# aif2 register map
Vendor: Texas Instruments
Peripheral module from a debugger description file (folder Keystone2).
Registers are 32-bit, read-write, no defined reset value unless marked. A register's access mark holds for its fields unless they carry their own. Offsets are as the file gives them; lines under a group give offsets from that group; [hi:lo] are bit positions; {n}, {i} and the like mark numbered series; 'fields as' and 'values as' point back to an identical list; <NAME> marks a mode.

## AIF2 (part 1 of 3)
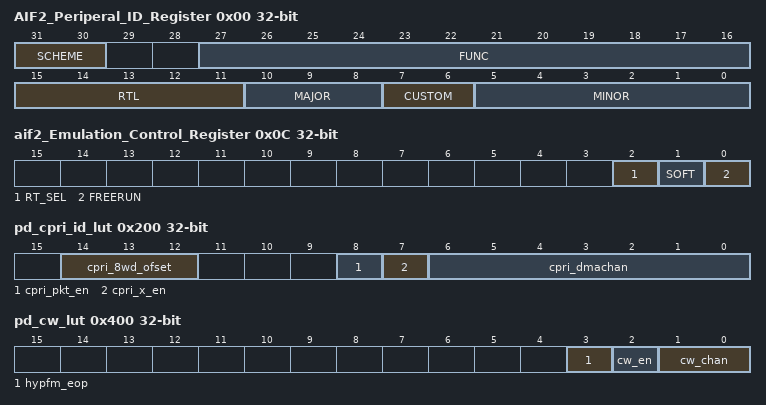
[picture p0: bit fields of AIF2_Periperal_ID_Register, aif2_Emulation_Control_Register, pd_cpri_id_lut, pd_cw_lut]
0x00 AIF2_Periperal_ID_Register ro
  [31:30] SCHEME — Current scheme
  [27:16] FUNC — Function code assigned to AIF2
  [15:11] RTL — RTL Version R code
  [10:8] MAJOR — Major revision X code
  [7:6] CUSTOM — Custom version code
  [5:0] MINOR — Minor revision Y code
0x04 AIF2_Scratch_Register — VC Scratch Register
  [31:0] Scratch — This is the VC Scratch Field.
0x08 AIF2_sw_reset wo — at sw sync
  [0] sw_rst — AIF2 software reset pulse
0x0C aif2_Emulation_Control_Register
  [2] RT_SEL — RT_SEL bit
  [1] SOFT — SOFT bit. This bit is ignored by the AIF2. AIF2 always performs a graceful SOFT stop
  [0] FREERUN — FREERUN bit
0x10 VC_Status_Register ro
  [0] EMU_HALT — Emulation halt status
0x200 pd_cpri_id_lut — (1 of 128, stride 4)
  [14:12] cpri_8wd_ofset — Fine AxC offset. Used in the front end of PD to align word data into QWords. bit \[1:0\] are offset into a QWord. bit\[2\] give RSA double QWork alignment. Bit\[2\] and corresponding axc_offset\[0\] should always be programmed to be identical
  [8] cpri_pkt_en — DBMF CPRI Stream LUT: dicates the cpri payload is to be used as AxC (normal) or Packet traffic. (note: the concept of packet traffic in CPRI payload is a feature extention of CPRI)
  [7] cpri_x_en — DBMF CPRI Stream LUT: enable-disable of channel, for each value of DBM X count.
  [6:0] cpri_dmachan — DBMF CPRI Stream LUT: AxC:used to map DBM X count to DMA channel. PKT:2 lsb indicates 0-3 PKT packing circuit (assumed 4B/5B encoding)
0x400 pd_cw_lut — (1 of 256, stride 4)
  [3] hypfm_eop — All possible CPRI CW per hyperframe. (Used for pkt_delim_ch HyperFrame delineation)Identifies last CW per HyperFrame for this channel
  [2] cw_en — All possible CPRI CW per hyperframe. Dicatates whether the control word should be captured at all
  [1:0] cw_chan — All possible CPRI CW per hyperframe are are mapped to one of four CPRI CW staging areas. This allow CPRI CW to be split into 4 differen streams.
0x4000 EE_VB_End_of_Interrupt_Register — This register supports the End of Interrupt (EOI) interface between the AIF2 and the external Interrupt Distributor Component used in the Highlander 0.1 Interrupt Architecture. It is a common register that is used for servicing both of the AIF2
  [7:0] eoi_vector — End of interrupt vector value that distinguishes which interrupt is being acknowledged. This value is outputted on the external eoi_vector interface of the AIF2.
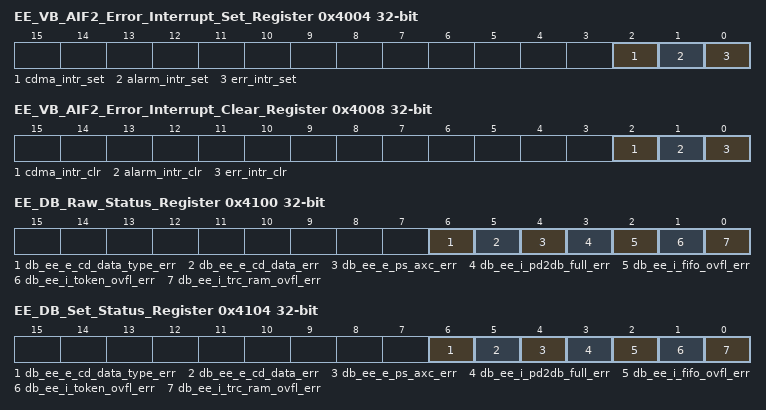
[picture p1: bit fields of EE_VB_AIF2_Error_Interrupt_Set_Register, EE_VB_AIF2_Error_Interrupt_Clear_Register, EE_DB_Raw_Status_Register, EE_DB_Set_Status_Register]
0x4004 EE_VB_AIF2_Error_Interrupt_Set_Register wo — This register allows software to create an AIF2 Error Interrupt or AIF2 Alarm Interrupt by writing bits in this register. This register is provided for debug and diagnostics.
  [2] cdma_intr_set — AIF2 CDMA Interrupt Set.
  [1] alarm_intr_set — AIF2 Alarm Interrupt Set.
  [0] err_intr_set — AIF2 Error Interrupt Set.
0x4008 EE_VB_AIF2_Error_Interrupt_Clear_Register wo — This register allows software to clear an AIF2 Error Interrupt or AIF2 Alarm Interrupt by writing bits in this register. This register is provided for debug and diagnostics.
  [2] cdma_intr_clr — AIF2 CDMA Interrupt Clear.
  [1] alarm_intr_clr — AIF2 Alarm Interrupt Clear.
  [0] err_intr_clr — AIF2 Error Interrupt Clear.
0x4100 EE_DB_Raw_Status_Register ro
  [6] db_ee_e_cd_data_type_err — DB Engress CDMA Data Error.
  [5] db_ee_e_cd_data_err — DB Ingress CDMA Data Error.
  [4] db_ee_e_ps_axc_err — DB Engress AXC Token Overflow Error.
  [3] db_ee_i_pd2db_full_err — DB Engress PM Token Overflow Error.
  [2] db_ee_i_fifo_ovfl_err — DB Ingress FIFO Overflow Error.
  [1] db_ee_i_token_ovfl_err — DB Ingress Token Overflow Error.
  [0] db_ee_i_trc_ram_ovfl_err — DB Ingress TRC Token Overflow Error.
0x4104 EE_DB_Set_Status_Register wo
  [6] db_ee_e_cd_data_type_err — DB Engress CDMA Data Error Set.
  [5] db_ee_e_cd_data_err — DB Ingress CDMA Data Error Set.
  [4] db_ee_e_ps_axc_err — DB Engress AXC Token Overflow Error Set.
  [3] db_ee_i_pd2db_full_err — DB Engress PM Token Overflow Error Set.
  [2] db_ee_i_fifo_ovfl_err — DB Ingress FIFO Overflow Error Set.
  [1] db_ee_i_token_ovfl_err — DB Ingress Token Overflow Error Set.
  [0] db_ee_i_trc_ram_ovfl_err — DB Ingress TRC Token Overflow Error Set.
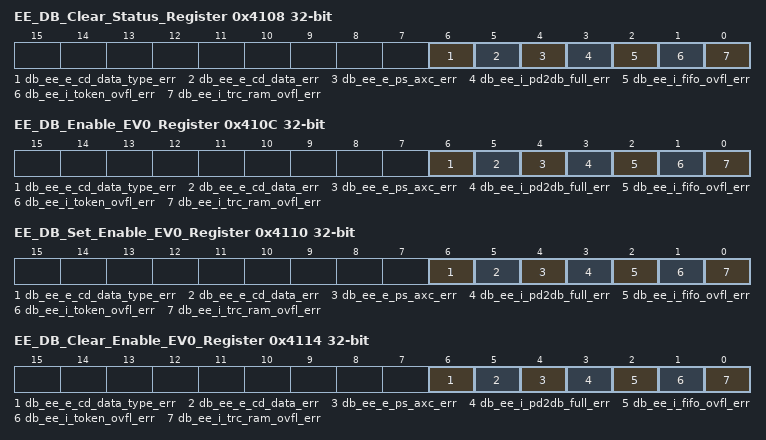
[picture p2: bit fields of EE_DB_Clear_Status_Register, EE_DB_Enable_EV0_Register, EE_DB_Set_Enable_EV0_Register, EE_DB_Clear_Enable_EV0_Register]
0x4108 EE_DB_Clear_Status_Register wo
  [6] db_ee_e_cd_data_type_err — DB Engress CDMA Data Error Clear.
  [5] db_ee_e_cd_data_err — DB Ingress CDMA Data Error Clear.
  [4] db_ee_e_ps_axc_err — DB Engress AXC Token Overflow Error Clear.
  [3] db_ee_i_pd2db_full_err — DB Engress PM Token Overflow Error Clear.
  [2] db_ee_i_fifo_ovfl_err — DB Ingress FIFO Overflow Error Clear.
  [1] db_ee_i_token_ovfl_err — DB Ingress Token Overflow Error Clear.
  [0] db_ee_i_trc_ram_ovfl_err — DB Ingress TRC Token Overflow Error Clear.
0x410C EE_DB_Enable_EV0_Register ro
  [6] db_ee_e_cd_data_type_err — DB Engress CDMA Data Error Enable.
  [5] db_ee_e_cd_data_err — DB Ingress CDMA Data Error Enable.
  [4] db_ee_e_ps_axc_err — DB Engress AXC Token Overflow Error Enable.
  [3] db_ee_i_pd2db_full_err — DB Engress PM Token Overflow Error Enable.
  [2] db_ee_i_fifo_ovfl_err — DB Ingress FIFO Overflow Error Enable.
  [1] db_ee_i_token_ovfl_err — DB Ingress Token Overflow Error Enable.
  [0] db_ee_i_trc_ram_ovfl_err — DB Ingress TRC Token Overflow Error Enable.
0x4110 EE_DB_Set_Enable_EV0_Register wo
  [6] db_ee_e_cd_data_type_err — DB Engress CDMA Data Error Enable Set.
  [5] db_ee_e_cd_data_err — DB Ingress CDMA Data Error Enable Set.
  [4] db_ee_e_ps_axc_err — DB Engress AXC Token Overflow Error Enable Set.
  [3] db_ee_i_pd2db_full_err — DB Engress PM Token Overflow Error Enable Set.
  [2] db_ee_i_fifo_ovfl_err — DB Ingress FIFO Overflow Error Enable Set.
  [1] db_ee_i_token_ovfl_err — DB Ingress Token Overflow Error Enable Set.
  [0] db_ee_i_trc_ram_ovfl_err — DB Ingress TRC Token Overflow Error Enable Set.
0x4114 EE_DB_Clear_Enable_EV0_Register wo
  [6] db_ee_e_cd_data_type_err — DB Engress CDMA Data Error Enable Clear.
  [5] db_ee_e_cd_data_err — DB Ingress CDMA Data Error Enable Clear.
  [4] db_ee_e_ps_axc_err — DB Engress AXC Token Overflow Error Enable Clear.
  [3] db_ee_i_pd2db_full_err — DB Engress PM Token Overflow Error Enable Clear.
  [2] db_ee_i_fifo_ovfl_err — DB Ingress FIFO Overflow Error Enable Clear.
  [1] db_ee_i_token_ovfl_err — DB Ingress Token Overflow Error Enable Clear.
  [0] db_ee_i_trc_ram_ovfl_err — DB Ingress TRC Token Overflow Error Enable Clear.
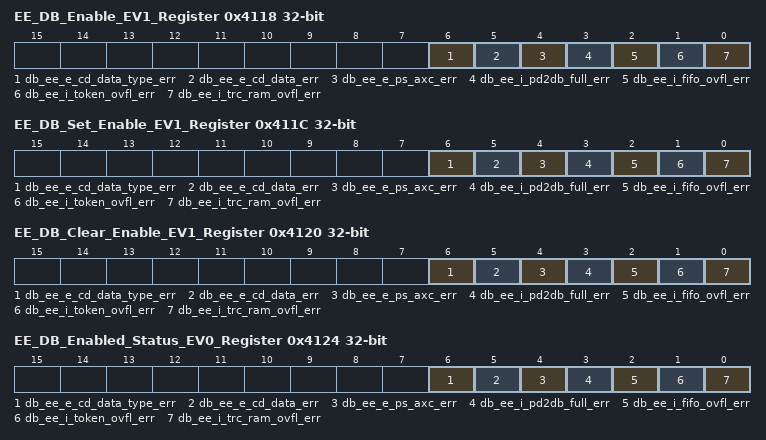
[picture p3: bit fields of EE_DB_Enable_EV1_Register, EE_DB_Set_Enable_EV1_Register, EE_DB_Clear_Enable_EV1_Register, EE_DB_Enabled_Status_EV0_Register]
0x4118 EE_DB_Enable_EV1_Register ro
  fields as EE_DB_Enable_EV0_Register
0x411C EE_DB_Set_Enable_EV1_Register wo
  fields as EE_DB_Set_Enable_EV0_Register
0x4120 EE_DB_Clear_Enable_EV1_Register wo
  fields as EE_DB_Clear_Enable_EV0_Register
0x4124 EE_DB_Enabled_Status_EV0_Register ro
  [6] db_ee_e_cd_data_type_err — DB Engress CDMA Data Error Enabled.
  [5] db_ee_e_cd_data_err — DB Ingress CDMA Data Error Enabled.
  [4] db_ee_e_ps_axc_err — DB Engress AXC Token Overflow Error Enabled.
  [3] db_ee_i_pd2db_full_err — DB Engress PM Token Overflow Error Enabled.
  [2] db_ee_i_fifo_ovfl_err — DB Ingress FIFO Overflow Error Enabled.
  [1] db_ee_i_token_ovfl_err — DB Ingress Token Overflow Error Enabled.
  [0] db_ee_i_trc_ram_ovfl_err — DB Ingress TRC Token Overflow Error Enabled.
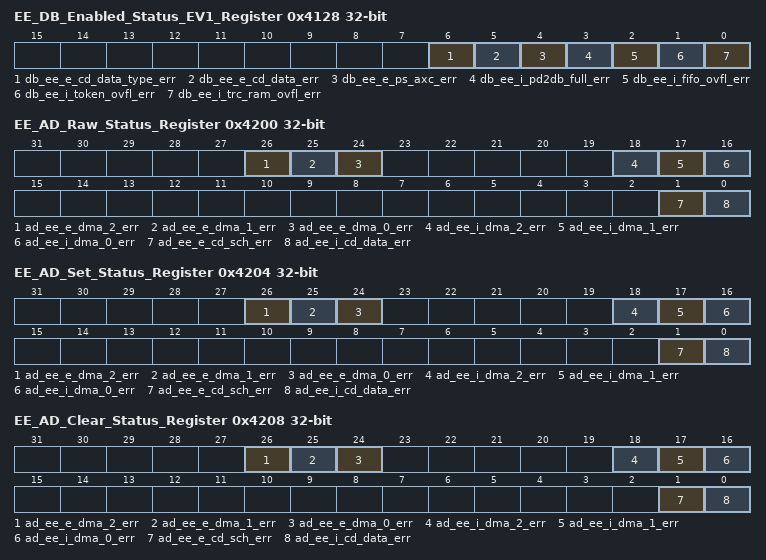
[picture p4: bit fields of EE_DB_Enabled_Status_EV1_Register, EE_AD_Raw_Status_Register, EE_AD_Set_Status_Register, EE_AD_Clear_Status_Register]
0x4128 EE_DB_Enabled_Status_EV1_Register ro
  fields as EE_DB_Enabled_Status_EV0_Register
0x4200 EE_AD_Raw_Status_Register ro
  [26] ad_ee_e_dma_2_err — AD Egress DMA Bit 2 Error.
  [25] ad_ee_e_dma_1_err — AD Egress DMA Bit 1 Error.
  [24] ad_ee_e_dma_0_err — AD Egress DMA Bit 0 Error.
  [18] ad_ee_i_dma_2_err — AD Ingress DMA Bit 2 Error.
  [17] ad_ee_i_dma_1_err — AD Ingress DMA Bit 1 Error.
  [16] ad_ee_i_dma_0_err — AD Ingress DMA Bit 0 Error.
  [1] ad_ee_e_cd_sch_err — AD Engress CDMA Scheduler Error.
  [0] ad_ee_i_cd_data_err — AD Egress CDMA Data Error.
0x4204 EE_AD_Set_Status_Register wo
  [26] ad_ee_e_dma_2_err — AD Egress DMA Bit 2 Error Set.
  [25] ad_ee_e_dma_1_err — AD Egress DMA Bit 1 Error Set.
  [24] ad_ee_e_dma_0_err — AD Egress DMA Bit 0 Error Set.
  [18] ad_ee_i_dma_2_err — AD Ingress DMA Bit 2 Error Set.
  [17] ad_ee_i_dma_1_err — AD Ingress DMA Bit 1 Error Set.
  [16] ad_ee_i_dma_0_err — AD Ingress DMA Bit 0 Error Set.
  [1] ad_ee_e_cd_sch_err — AD Engress CDMA Scheduler Error Set.
  [0] ad_ee_i_cd_data_err — AD Egress CDMA Data Error Set.
0x4208 EE_AD_Clear_Status_Register wo
  [26] ad_ee_e_dma_2_err — AD Egress DMA Bit 2 Error Clear.
  [25] ad_ee_e_dma_1_err — AD Egress DMA Bit 1 Error Clear.
  [24] ad_ee_e_dma_0_err — AD Egress DMA Bit 0 Error Clear.
  [18] ad_ee_i_dma_2_err — AD Ingress DMA Bit 2 Error Clear.
  [17] ad_ee_i_dma_1_err — AD Ingress DMA Bit 1 Error Clear.
  [16] ad_ee_i_dma_0_err — AD Ingress DMA Bit 0 Error Clear.
  [1] ad_ee_e_cd_sch_err — AD Engress CDMA Scheduler Error Clear.
  [0] ad_ee_i_cd_data_err — AD Egress CDMA Data Error Clear.
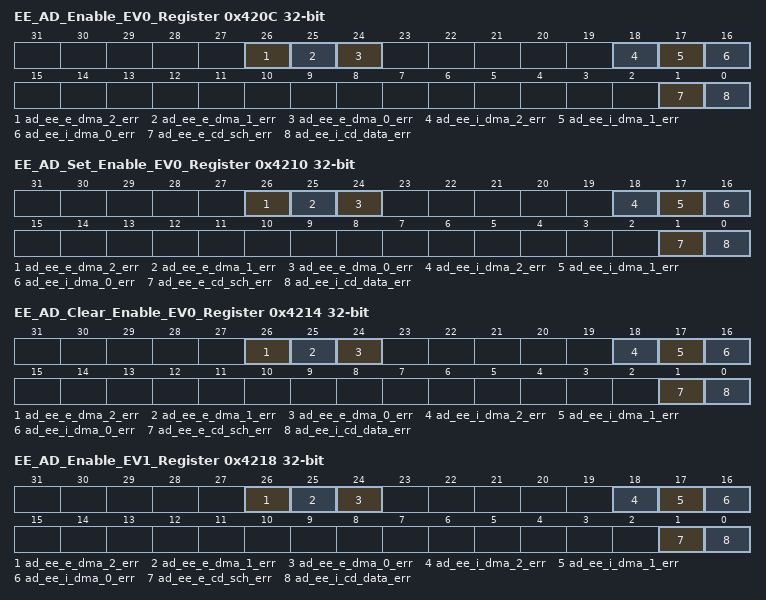
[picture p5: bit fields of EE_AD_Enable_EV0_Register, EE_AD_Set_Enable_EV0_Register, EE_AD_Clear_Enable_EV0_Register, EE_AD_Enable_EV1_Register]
0x420C EE_AD_Enable_EV0_Register ro
  [26] ad_ee_e_dma_2_err — AD Egress DMA Bit 2 Error Enable.
  [25] ad_ee_e_dma_1_err — AD Egress DMA Bit 1 Error Enable.
  [24] ad_ee_e_dma_0_err — AD Egress DMA Bit 0 Error Enable.
  [18] ad_ee_i_dma_2_err — AD Ingress DMA Bit 2 Error Enable.
  [17] ad_ee_i_dma_1_err — AD Ingress DMA Bit 1 Error Enable.
  [16] ad_ee_i_dma_0_err — AD Ingress DMA Bit 0 Error Enable.
  [1] ad_ee_e_cd_sch_err — AD Engress CDMA Scheduler Error Enable.
  [0] ad_ee_i_cd_data_err — AD Egress CDMA Data Error Enable.
0x4210 EE_AD_Set_Enable_EV0_Register wo
  [26] ad_ee_e_dma_2_err — AD Egress DMA Bit 2 Error Enable Set.
  [25] ad_ee_e_dma_1_err — AD Egress DMA Bit 1 Error Enable Set.
  [24] ad_ee_e_dma_0_err — AD Egress DMA Bit 0 Error Enable Set.
  [18] ad_ee_i_dma_2_err — AD Ingress DMA Bit 2 Error Enable Set.
  [17] ad_ee_i_dma_1_err — AD Ingress DMA Bit 1 Error Enable Set.
  [16] ad_ee_i_dma_0_err — AD Ingress DMA Bit 0 Error Enable Set.
  [1] ad_ee_e_cd_sch_err — AD Engress CDMA Scheduler Error Enable Set.
  [0] ad_ee_i_cd_data_err — AD Egress CDMA Data Error Enable Set.
0x4214 EE_AD_Clear_Enable_EV0_Register wo
  [26] ad_ee_e_dma_2_err — AD Egress DMA Bit 2 Error Enable Clear.
  [25] ad_ee_e_dma_1_err — AD Egress DMA Bit 1 Error Enable Clear.
  [24] ad_ee_e_dma_0_err — AD Egress DMA Bit 0 Error Enable Clear.
  [18] ad_ee_i_dma_2_err — AD Ingress DMA Bit 2 Error Enable Clear.
  [17] ad_ee_i_dma_1_err — AD Ingress DMA Bit 1 Error Enable Clear.
  [16] ad_ee_i_dma_0_err — AD Ingress DMA Bit 0 Error Enable Clear.
  [1] ad_ee_e_cd_sch_err — AD Engress CDMA Scheduler Error Enable Clear.
  [0] ad_ee_i_cd_data_err — AD Egress CDMA Data Error Enable Clear.
0x4218 EE_AD_Enable_EV1_Register ro
  fields as EE_AD_Enable_EV0_Register
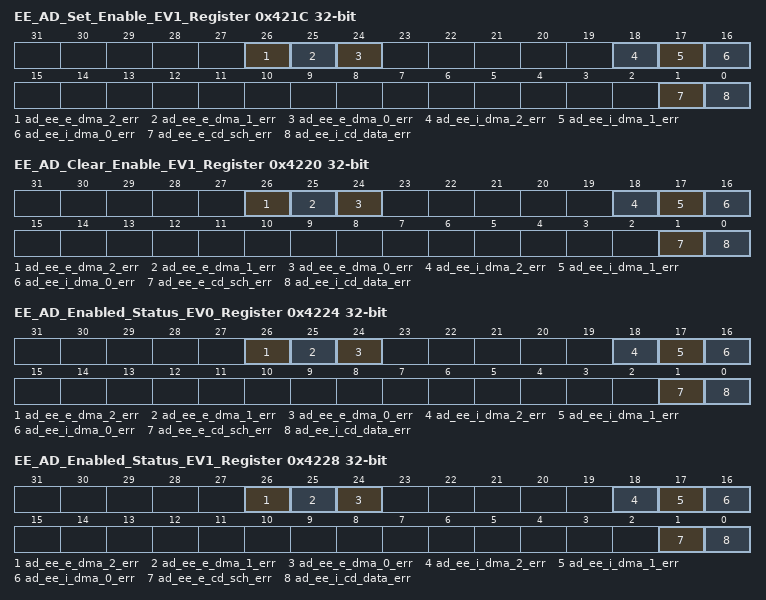
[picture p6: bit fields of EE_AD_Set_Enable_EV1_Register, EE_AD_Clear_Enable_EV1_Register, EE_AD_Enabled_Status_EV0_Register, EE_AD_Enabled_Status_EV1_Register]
0x421C EE_AD_Set_Enable_EV1_Register wo
  fields as EE_AD_Set_Enable_EV0_Register
0x4220 EE_AD_Clear_Enable_EV1_Register wo
  fields as EE_AD_Clear_Enable_EV0_Register
0x4224 EE_AD_Enabled_Status_EV0_Register ro
  [26] ad_ee_e_dma_2_err — AD Egress DMA Bit 2 Error Enabled.
  [25] ad_ee_e_dma_1_err — AD Egress DMA Bit 1 Error Enabled.
  [24] ad_ee_e_dma_0_err — AD Egress DMA Bit 0 Error Enabled.
  [18] ad_ee_i_dma_2_err — AD Ingress DMA Bit 2 Error Enabled.
  [17] ad_ee_i_dma_1_err — AD Ingress DMA Bit 1 Error Enabled.
  [16] ad_ee_i_dma_0_err — AD Ingress DMA Bit 0 Error Enabled.
  [1] ad_ee_e_cd_sch_err — AD Engress CDMA Scheduler Error Enabled.
  [0] ad_ee_i_cd_data_err — AD Egress CDMA Data Error Enabled.
0x4228 EE_AD_Enabled_Status_EV1_Register ro
  fields as EE_AD_Enabled_Status_EV0_Register
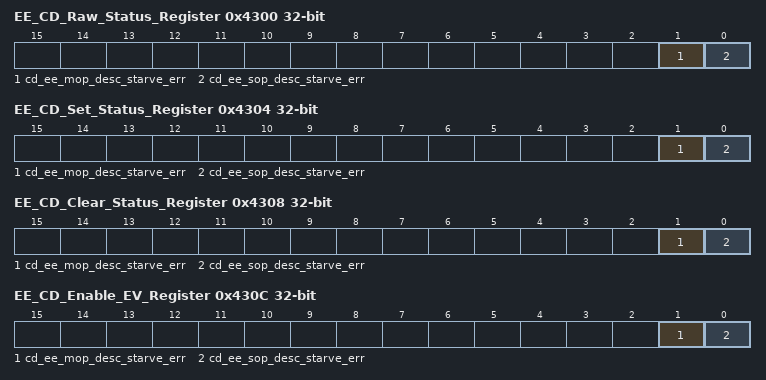
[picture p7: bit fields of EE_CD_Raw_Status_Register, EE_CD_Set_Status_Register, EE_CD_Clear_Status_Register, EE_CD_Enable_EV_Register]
0x4300 EE_CD_Raw_Status_Register ro
  [1] cd_ee_mop_desc_starve_err — CD MOP Desc. Starve Error.
  [0] cd_ee_sop_desc_starve_err — CD SOP Desc. Starve Error.
0x4304 EE_CD_Set_Status_Register wo
  [1] cd_ee_mop_desc_starve_err — CD MOP Desc. Starve Error Set.
  [0] cd_ee_sop_desc_starve_err — CD SOP Desc. Starve Error Set.
0x4308 EE_CD_Clear_Status_Register wo
  [1] cd_ee_mop_desc_starve_err — CD MOP Desc. Starve Error Clear.
  [0] cd_ee_sop_desc_starve_err — CD SOP Desc. Starve Error Clear.
0x430C EE_CD_Enable_EV_Register ro — EE CD Enable EV0 Register
  [1] cd_ee_mop_desc_starve_err — CD MOP Desc. Starve Error Enable.
  [0] cd_ee_sop_desc_starve_err — CD SOP Desc. Starve Error Enable.
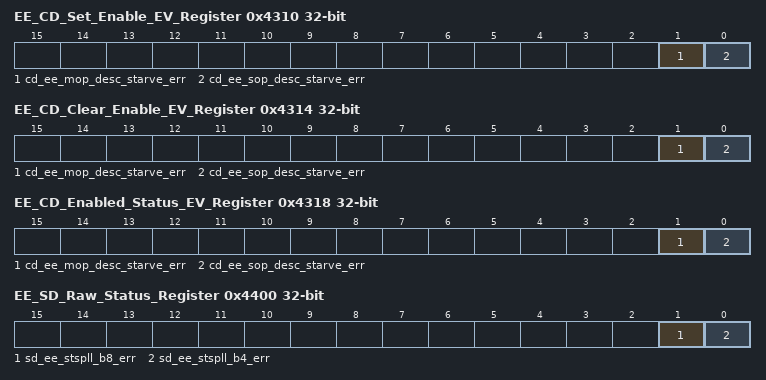
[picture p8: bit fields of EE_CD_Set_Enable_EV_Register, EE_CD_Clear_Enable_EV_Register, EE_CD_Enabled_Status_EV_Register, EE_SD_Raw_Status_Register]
0x4310 EE_CD_Set_Enable_EV_Register wo — EE CD Set Enable EV0 Register
  [1] cd_ee_mop_desc_starve_err — CD MOP Desc. Starve Error Enable Set.
  [0] cd_ee_sop_desc_starve_err — CD SOP Desc. Starve Error Enable Set.
0x4314 EE_CD_Clear_Enable_EV_Register wo — EE CD Clear Enable EV0 Register
  [1] cd_ee_mop_desc_starve_err — CD MOP Desc. Starve Error Enable Clear.
  [0] cd_ee_sop_desc_starve_err — CD SOP Desc. Starve Error Enable Clear.
0x4318 EE_CD_Enabled_Status_EV_Register ro — EE CD Enabled Status EV0 Register
  [1] cd_ee_mop_desc_starve_err — CD MOP Desc. Starve Error Enabled.
  [0] cd_ee_sop_desc_starve_err — CD SOP Desc. Starve Error Enabled.
0x4400 EE_SD_Raw_Status_Register ro
  [1] sd_ee_stspll_b8_err — SD B8 PLL Error.
  [0] sd_ee_stspll_b4_err — SD B4 PLL Error.
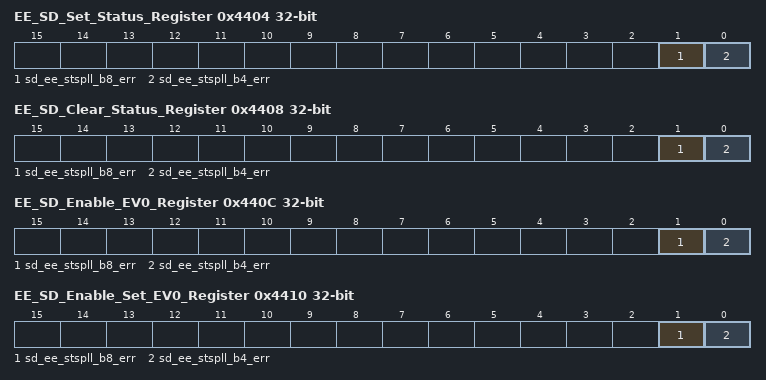
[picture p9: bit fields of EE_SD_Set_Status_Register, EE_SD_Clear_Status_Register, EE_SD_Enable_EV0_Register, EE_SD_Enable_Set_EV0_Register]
0x4404 EE_SD_Set_Status_Register wo
  [1] sd_ee_stspll_b8_err — SD B8 PLL Error Set.
  [0] sd_ee_stspll_b4_err — SD B4 PLL Error Set.
0x4408 EE_SD_Clear_Status_Register wo
  [1] sd_ee_stspll_b8_err — SD B8 PLL Error Clear
  [0] sd_ee_stspll_b4_err — SD B4 PLL Error Clear
0x440C EE_SD_Enable_EV0_Register ro
  [1] sd_ee_stspll_b8_err — SD B8 PLL Error Enable.
  [0] sd_ee_stspll_b4_err — SD B4 PLL Error Enable.
0x4410 EE_SD_Enable_Set_EV0_Register wo
  [1] sd_ee_stspll_b8_err — SD B8 PLL Error Set Enable.
  [0] sd_ee_stspll_b4_err — SD B4 PLL Error Set Enable.
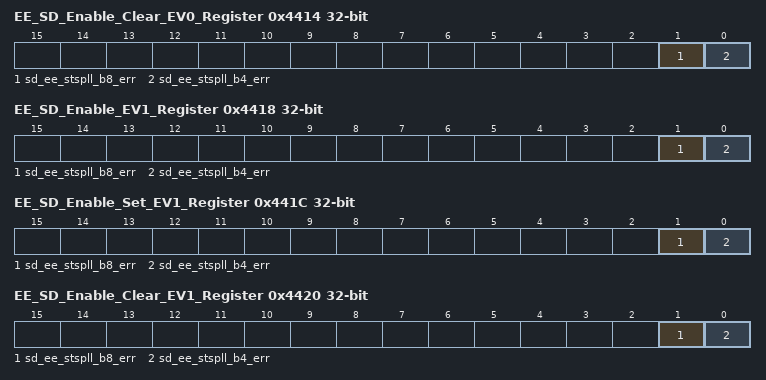
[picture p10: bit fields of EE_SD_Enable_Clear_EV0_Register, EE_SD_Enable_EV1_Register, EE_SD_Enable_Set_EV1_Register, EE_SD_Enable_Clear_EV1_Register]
0x4414 EE_SD_Enable_Clear_EV0_Register wo
  [1] sd_ee_stspll_b8_err — SD B8 PLL Error Clear Enable.
  [0] sd_ee_stspll_b4_err — SD B4 PLL Error Clear Enable.
0x4418 EE_SD_Enable_EV1_Register ro
  fields as EE_SD_Enable_EV0_Register
0x441C EE_SD_Enable_Set_EV1_Register wo
  fields as EE_SD_Enable_Set_EV0_Register
0x4420 EE_SD_Enable_Clear_EV1_Register wo
  fields as EE_SD_Enable_Clear_EV0_Register
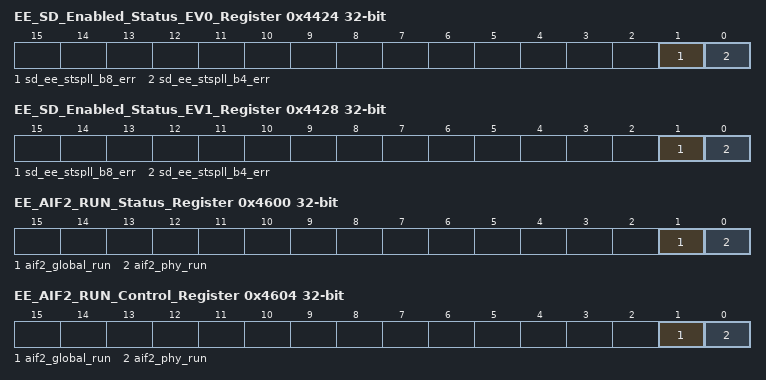
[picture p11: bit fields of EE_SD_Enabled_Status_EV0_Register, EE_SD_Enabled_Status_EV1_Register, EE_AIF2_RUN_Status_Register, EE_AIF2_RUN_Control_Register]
0x4424 EE_SD_Enabled_Status_EV0_Register ro
  [1] sd_ee_stspll_b8_err — SD B8 PLL Error Enabled.
  [0] sd_ee_stspll_b4_err — SD B4 PLL Error Enabled.
0x4428 EE_SD_Enabled_Status_EV1_Register ro
  fields as EE_SD_Enabled_Status_EV0_Register
0x4500 EE_VC_Raw_Status_Register ro
  [0] vc_ee_vbus_err — SD B4 PLL Error.
0x4504 EE_VC_Set_Status_Register wo
  [0] vc_ee_vbus_err — EE VC VBUS Error Set.
0x4508 EE_VC_Clear_Status_Register wo
  [0] vc_ee_vbus_err — EE VC VBUS Error Clear
0x450C EE_VC_Enable_EV0_Register ro
  [0] vc_ee_vbus_err — EE VC VBUS Error Enable.
0x4510 EE_VC_Enable_Set_EV0_Register wo
  [0] vc_ee_vbus_err — EE VC VBUS Error Set Enable.
0x4514 EE_VC_Enable_Clear_EV0_Register wo
  [0] vc_ee_vbus_err — EE VC VBUS Error Clear Enable.
0x4518 EE_VC_Enable_EV1_Register ro
  [0] vc_ee_vbus_err — EE VC VBUS Error Enable.
0x451C EE_VC_Enable_Set_EV1_Register wo
  [0] vc_ee_vbus_err — EE VC VBUS Error Set Enable.
0x4520 EE_VC_Enable_Clear_EV1_Register wo
  [0] vc_ee_vbus_err — EE VC VBUS Error Clear Enable.
0x4524 EE_VC_Enabled_Status_EV0_Register ro
  [0] vc_ee_vbus_err — EE VC VBUS Error Enabled.
0x4528 EE_VC_Enabled_Status_EV1_Register ro
  [0] vc_ee_vbus_err — EE VC VBUS Error Enabled
0x4600 EE_AIF2_RUN_Status_Register ro — This register is used to indicate the state of AIF2
  [1] aif2_global_run — This bit indicates the overall state of the AIF2.
  [0] aif2_phy_run — This bit indicates the state of the AIF2 Phy section.
0x4604 EE_AIF2_RUN_Control_Register wo — This register is used to indicate the state of AIF2
  fields as EE_AIF2_RUN_Status_Register
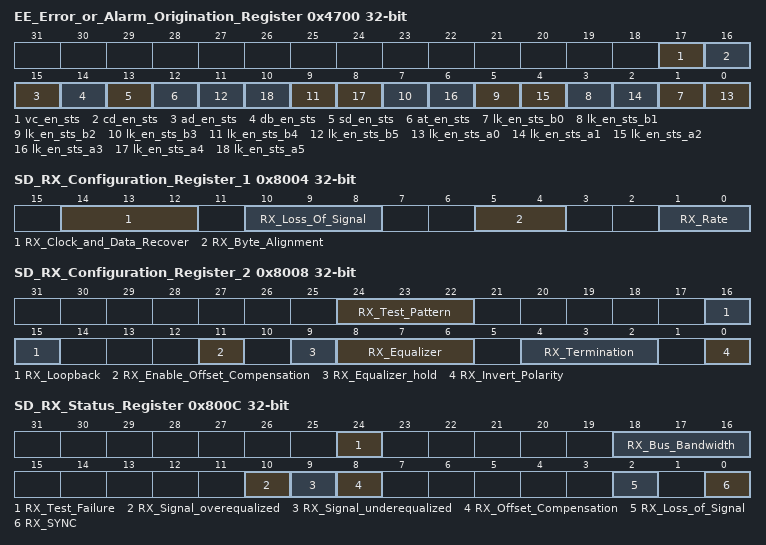
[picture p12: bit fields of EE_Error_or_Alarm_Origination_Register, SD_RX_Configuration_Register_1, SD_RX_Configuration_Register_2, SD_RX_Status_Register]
0x4700 EE_Error_or_Alarm_Origination_Register ro — EE Register used to determine which EN_STSregister contains the error/alarm that caused an event
  [17] vc_en_sts — VC_EN_STS register indication.
  [16] cd_en_sts — CD_EN_STS register indication.
  [15] ad_en_sts — AD_EN_STS register indication.
  [14] db_en_sts — DB_EN_STS register indication.
  [13] sd_en_sts — SD_EN_STS register indication.
  [12] at_en_sts — AT_EN_STS register indication.
  [2n+1] lk_en_sts_b{n} (n=0..5) — EE_LK_EN_STS_B{n} register indication.
  [2n] lk_en_sts_a{n} (n=0..5) — EE_LK_EN_STS_A{n} register indication.
0x8000 SD_RX_Enable_Configuration_Register — (1 of 6, stride 2048)
  [0] Enable_RX — The receiver Ser-des macro should be enabled once all the Ser-des configurations are complete, and the PLL has acquired lock.
0x8004 SD_RX_Configuration_Register_1 — (1 of 6, stride 2048)
  [14:12] RX_Clock_and_Data_Recover — Clock/data recovery. Configures the clock/data recovery algorithm.
  [10:8] RX_Loss_Of_Signal — The LOSi bits should be set to 2b10 to allow Loss of signal detection by the Ser-des macro.
  [5:4] RX_Byte_Alignment — The receiver frame synchronizer must control the byte alignment feature of each receiver so that a jog can be initiated based on detection of non-alignment. The ALIGNi bits must be set to 2b00 for normal operation.
  [1:0] RX_Rate — The AIF2 antenna interface link configuration registers must reflect the sample rate of each receiver as 2x, 4x, 8x so that the receiver logic is aware of the rate setting. These rates are listed in the following table.
0x8008 SD_RX_Configuration_Register_2 — (1 of 6, stride 2048)
  [24:22] RX_Test_Pattern — Enables and selects test patterns. Enables and selects verification of one of three PRBS patterns, a user defined pattern, or a clock test pattern.
  [16:15] RX_Loopback — The receiver frame synchronizer must have knowledge that each Ser-des port had been placed in Tx to Rx loopback so that the receiver can suppress events due to the realignment of the received frames. These bits should be set to 2b00 for normal operation.
  [11] RX_Enable_Offset_Compensation — Enable Offset Compensation. Enables samplers offset compensation.
  [9] RX_Equalizer_hold — Hold Equalizer. Holds equalizer in the current state.
  [8:6] RX_Equalizer — Equalizer. Enables and configures the equalizer to compensate for loss in the transmission media.
  [4:2] RX_Termination — Termination. Selects the input termination options suitable for AC or DC coupled scenarios.
  [0] RX_Invert_Polarity — Invert Polarity. Inverts the polarity of RXPi and RXNi.
0x800C SD_RX_Status_Register ro — (1 of 6, stride 2048)
  [24] RX_Test_Failure — Test Failure. Driven high when an error is encountered during a test sequence executed on an individual channel. Synchronous to RXBCLK.
  [18:16] RX_Bus_Bandwidth — The receiver bus bandwidth is fixed in hardware to 20 bits and is not configurable through an MMR. However the value that reflects a 20 bit bus width will be read of the configuration register is read.
  [10] RX_Signal_overequalized — Driven high during equalizer analysis if over equalized.
  [9] RX_Signal_underequalized — Driven high during equalizer analysis if under equalized.
  [8] RX_Offset_Compensation — Offset compensation in progress. Driven high asynchronously during offset compensation.
  [2] RX_Loss_of_Signal — The receiver frame synchronizer must have knowledge that each Ser-des port had detected a loss of signal condition so that the receiver can suppress events due to a loss of frame synchronization.
  [0] RX_SYNC — If the alignment feature of the Ser-des is used by hardware, the receiver frame synchronizer must have knowledge that each Ser-des port had completed a requested byte alignment so that the byte alignment control logic can operate.
0x8010 SD_TX_Enable_Configuration_Register — (1 of 6, stride 2048)
  [0] Enable_TX — The receiver Ser-des macro should be enabled once all the Ser-des configurations are complete, and the PLL has acquired lock.
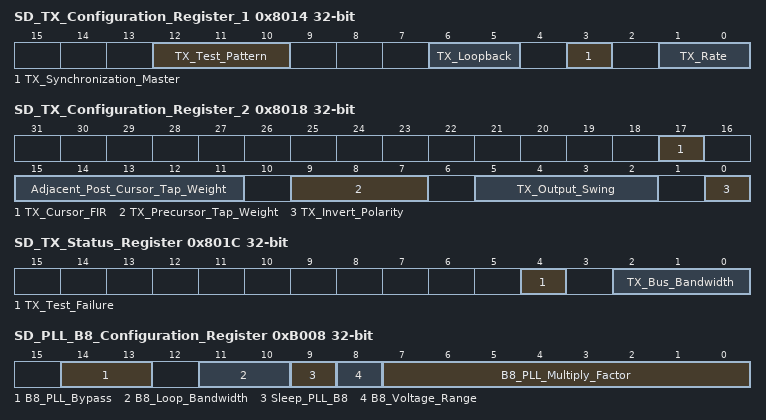
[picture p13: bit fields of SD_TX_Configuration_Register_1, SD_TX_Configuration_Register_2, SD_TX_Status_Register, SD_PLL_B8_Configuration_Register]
0x8014 SD_TX_Configuration_Register_1 — (1 of 6, stride 2048)
  [12:10] TX_Test_Pattern — Enables and selects test patterns. Enables and selects verification of one of three PRBS patterns, a user defined pattern, or a clock test pattern.
  [6:5] TX_Loopback — Loopback. Enable loopback high to assert.
  [3] TX_Synchronization_Master — Synchronisation Master. Enables the channel as the master lane for synchronization purposes. Tie high unless implementing macro to macro synchronization.
  [1:0] TX_Rate — The AIF2 antenna interface link configuration registers must reflect the sample rate of each transmitter as 2x, 4x, 8x so that the transmitter logic is aware of the rate setting. Because AIF2 utilizes the system clock of 307.2 Mhz generated by one of the
0x8018 SD_TX_Configuration_Register_2 — (1 of 6, stride 2048)
  [17] TX_Cursor_FIR — Transmitter pre and post cursor FIR filter Update. Update control of FIR taps weights. Fields TWPRE and TWPST1 can be updated when TXBCLK and this input are both high.
  [15:11] Adjacent_Post_Cursor_Tap_Weight — Adjacent post cursor Tap Weight. Selects one of 32 output tap weights for TX waveform conditioning.
  [9:7] TX_Precursor_Tap_Weight — Precursor Tap Weight. Selects one of 8 output tap weights for TX waveform conditioning. The settings are from 0 to 17.5% in 2.5% steps.
  [5:2] TX_Output_Swing — Output swing. Selects one of 16 output amplitude settings between 100 and 850 mVdfpp.
  [0] TX_Invert_Polarity — Invert Polarity. Inverts the polarity of TXPi and TXNi.
0x801C SD_TX_Status_Register ro — (1 of 6, stride 2048)
  [4] TX_Test_Failure — Test Failure. Driven high when an error is encountered during a test sequence executed on an individual channel. Synchronous to TXBCLK.
  [2:0] TX_Bus_Bandwidth — The transmitter bus bandwidth is fixed in hardware to 20 bits and is not configurable through an MMR. However the value that reflects a 20 bit bus width will be read of the configuration register is read.
0xB000 SD_PLL_B8_Enable_Configuration_Register — B8 PLL configuration Register
  [0] Enable_B8_PLL — The transmit and receive Ser-des functions requires that the PLL has been enabled.
0xB004 SD_PLL_B4_Enable_Configuration_Register — B4 PLL configuration Register
  [0] Enable_B4_PLL — The transmit and receive Ser-des functions requires that the PLL has been enabled.
0xB008 SD_PLL_B8_Configuration_Register — B8 PLL configuration Register
  [14:13] B8_PLL_Bypass — Clock Bypass. Facilitates bypassing of the PLL with either REFCLKP/N or TESTCLKT, and bypassing of the recovered receiver clock with TESTCLKR.
  [11:10] B8_Loop_Bandwidth — Loop Bandwidth. Specifiy loop bandwidth.
  [9] Sleep_PLL_B8 — Puts the B8 PLL into sleep state when high.
  [8] B8_Voltage_Range — Select between and and low range.
  [7:0] B8_PLL_Multiply_Factor — The PLL of the Ser-des module must be between 1.5625 Ghz and 3.125 Ghz for proper ser-des operation. The optimal reference clock frequency should be between 300 and 800 Mhz, although a low frequency of 100 Mhz can be used but at the expense of quality of
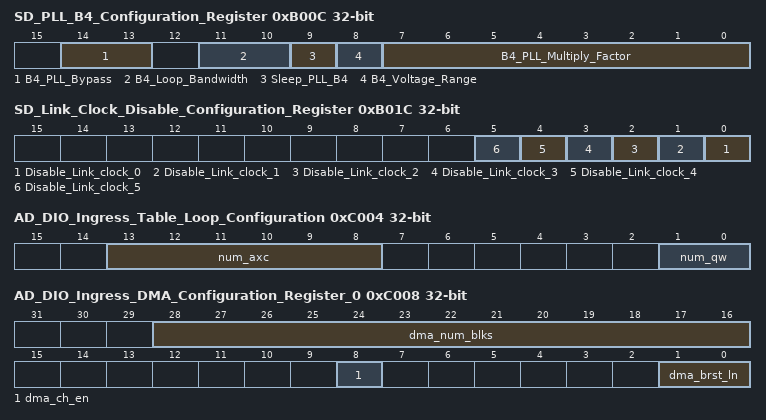
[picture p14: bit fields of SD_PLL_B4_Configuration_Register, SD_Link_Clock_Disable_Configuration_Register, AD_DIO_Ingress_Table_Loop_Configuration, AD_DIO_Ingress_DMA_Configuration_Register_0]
0xB00C SD_PLL_B4_Configuration_Register — B4 PLL configuration Register
  [14:13] B4_PLL_Bypass — Clock Bypass. Facilitates bypassing of the PLL with either REFCLKP/N or TESTCLKT, and bypassing of the recovered receiver clock with TESTCLKR.
  [11:10] B4_Loop_Bandwidth — Loop Bandwidth. Specifiy loop bandwidth.
  [9] Sleep_PLL_B4 — Puts the B4 PLL into sleep state when high.
  [8] B4_Voltage_Range — Select between and and low range.
  [7:0] B4_PLL_Multiply_Factor — The PLL of the Ser-des module must be between 1.5625 Ghz and 3.125 Ghz for proper ser-des operation. The optimal reference clock frequency should be between 300 and 800 Mhz, although a low frequency of 100 Mhz can be used but at the expense of quality of
0xB010 SD_PLL_B8_Status_Register ro — B8 PLL Status Register
  [0] B8_PLL_Lock — The transmitter and receiver Ser-des macros require that the PLL has acquired lock to operate. The lock status should be validated before the Ser-des macros are enabled..
0xB014 SD_PLL_B4_Status_Register ro — B4 PLL Status Register
  [0] B4_PLL_Lock — The transmitter and receiver Ser-des macros require that the PLL has acquired lock to operate. The lock status should be validated before the Ser-des macros are enabled..
0xB018 SD_Clock_select_Configuration_Register — Clock selection
  [0] Enable_RX — The TX byte clock from either B8 or B4 SERDES link 0 will be selected as sys_clk once the PLL has acquired lock.
0xB01C SD_Link_Clock_Disable_Configuration_Register — Link clock Enable Register
  [n] Disable_Link_clock_{n} (n=0..5) — The clock for this link will be gated off when set.
0xC000 AD_DIO_Ingress_Table_Select_Register — (1 of 3, stride 256)
  [0] bcn_table_sel — Selects which buffer channel number table for the DMA engine to use
0xC004 AD_DIO_Ingress_Table_Loop_Configuration — (1 of 3, stride 256)
  [13:8] num_axc — Sets the number of AxCs (i.e. 0 to 63 ... 1 to 64 AxCs).
  [1:0] num_qw — Sets the number of quad words per AxC.
0xC008 AD_DIO_Ingress_DMA_Configuration_Register_0 — (1 of 3, stride 256)
  [28:16] dma_num_blks — Set the number of data blocks to transfer before wrapping back to dma_base_addr.
  [8] dma_ch_en — Enable channel DMA.
  [1:0] dma_brst_ln — Sets the maximum DMA burst length.
0xC00C AD_DIO_Ingress_DMA_Configuration_Register_1 — (1 of 3, stride 256)
  [27:0] dma_base_addr — Sets the VBUS destination base address (upper 28 bits of 32 bit data bus).
0xC010 AD_DIO_Ingress_DMA_Configuration_Register_2 — (1 of 3, stride 256)
  [27:16] dma_blk_addr_stride — Sets the DMA block address stride (in multiples of 0x10).
  [11:0] dma_brst_addr_stride — Sets the DMA burst address stride (in multiples of 0x10). After each DMA burst, the DMA address will increment by this amount.
0xC014 AD_DIO_Ingress_BCN_Table_0_Row_0_Register — (1 of 3, stride 256)
  [8n+6:8n] dbcn{n} (n=0..3) — Data Buffer Channel Number {n}
0xC018 AD_DIO_Ingress_BCN_Table_0_Row_1_Register — (1 of 3, stride 256)
  [8n-26:8n-32] dbcn{n} (n=4..7) — Data Buffer Channel Number {n}
0xC01C AD_DIO_Ingress_BCN_Table_0_Row_2_Register — (1 of 3, stride 256)
  [8n-58:8n-64] dbcn{n} (n=8..11) — Data Buffer Channel Number {n}
0xC020 AD_DIO_Ingress_BCN_Table_0_Row_3_Register — (1 of 3, stride 256)
  [8n-90:8n-96] dbcn{n} (n=12..15) — Data Buffer Channel Number {n}
0xC024 AD_DIO_Ingress_BCN_Table_0_Row_4_Register — (1 of 3, stride 256)
  [8n-122:8n-128] dbcn{n} (n=16..19) — Data Buffer Channel Number {n}
0xC028 AD_DIO_Ingress_BCN_Table_0_Row_5_Register — (1 of 3, stride 256)
  [8n-154:8n-160] dbcn{n} (n=20..23) — Data Buffer Channel Number {n}
0xC02C AD_DIO_Ingress_BCN_Table_0_Row_6_Register — (1 of 3, stride 256)
  [8n-186:8n-192] dbcn{n} (n=24..27) — Data Buffer Channel Number {n}
0xC030 AD_DIO_Ingress_BCN_Table_0_Row_7_Register — (1 of 3, stride 256)
  [8n-218:8n-224] dbcn{n} (n=28..31) — Data Buffer Channel Number {n}
0xC034 AD_DIO_Ingress_BCN_Table_0_Row_8_Register — (1 of 3, stride 256)
  [8n-250:8n-256] dbcn{n} (n=32..35) — Data Buffer Channel Number {n}
0xC038 AD_DIO_Ingress_BCN_Table_0_Row_9_Register — (1 of 3, stride 256)
  [8n-282:8n-288] dbcn{n} (n=36..39) — Data Buffer Channel Number {n}
0xC03C AD_DIO_Ingress_BCN_Table_0_Row_10_Register — (1 of 3, stride 256)
  [8n-314:8n-320] dbcn{n} (n=40..43) — Data Buffer Channel Number {n}
0xC040 AD_DIO_Ingress_BCN_Table_0_Row_11_Register — (1 of 3, stride 256)
  [8n-346:8n-352] dbcn{n} (n=44..47) — Data Buffer Channel Number {n}
0xC044 AD_DIO_Ingress_BCN_Table_0_Row_12_Register — (1 of 3, stride 256)
  [8n-378:8n-384] dbcn{n} (n=48..51) — Data Buffer Channel Number {n}
0xC048 AD_DIO_Ingress_BCN_Table_0_Row_13_Register — (1 of 3, stride 256)
  [8n-410:8n-416] dbcn{n} (n=52..55) — Data Buffer Channel Number {n}
0xC04C AD_DIO_Ingress_BCN_Table_0_Row_14_Register — (1 of 3, stride 256)
  [8n-442:8n-448] dbcn{n} (n=56..59) — Data Buffer Channel Number {n}
0xC050 AD_DIO_Ingress_BCN_Table_0_Row_15_Register — (1 of 3, stride 256)
  [8n-474:8n-480] dbcn{n} (n=60..63) — Data Buffer Channel Number {n}
0xC054 AD_DIO_Ingress_BCN_Table_1_Row_0_Register — (1 of 3, stride 256)
  [8n+6:8n] dbcn{n} (n=0..3) — Data Buffer Channel Number {n}
0xC058 AD_DIO_Ingress_BCN_Table_1_Row_1_Register — (1 of 3, stride 256)
  [8n-26:8n-32] dbcn{n} (n=4..7) — Data Buffer Channel Number {n}
0xC05C AD_DIO_Ingress_BCN_Table_1_Row_2_Register — (1 of 3, stride 256)
  [8n-58:8n-64] dbcn{n} (n=8..11) — Data Buffer Channel Number {n}
0xC060 AD_DIO_Ingress_BCN_Table_1_Row_3_Register — (1 of 3, stride 256)
  [8n-90:8n-96] dbcn{n} (n=12..15) — Data Buffer Channel Number {n}
0xC064 AD_DIO_Ingress_BCN_Table_1_Row_4_Register — (1 of 3, stride 256)
  [8n-122:8n-128] dbcn{n} (n=16..19) — Data Buffer Channel Number {n}
0xC068 AD_DIO_Ingress_BCN_Table_1_Row_5_Register — (1 of 3, stride 256)
  [8n-154:8n-160] dbcn{n} (n=20..23) — Data Buffer Channel Number {n}
0xC06C AD_DIO_Ingress_BCN_Table_1_Row_6_Register — (1 of 3, stride 256)
  [8n-186:8n-192] dbcn{n} (n=24..27) — Data Buffer Channel Number {n}
0xC070 AD_DIO_Ingress_BCN_Table_1_Row_7_Register — (1 of 3, stride 256)
  [8n-218:8n-224] dbcn{n} (n=28..31) — Data Buffer Channel Number {n}
0xC074 AD_DIO_Ingress_BCN_Table_1_Row_8_Register — (1 of 3, stride 256)
  [8n-250:8n-256] dbcn{n} (n=32..35) — Data Buffer Channel Number {n}
0xC078 AD_DIO_Ingress_BCN_Table_1_Row_9_Register — (1 of 3, stride 256)
  [8n-282:8n-288] dbcn{n} (n=36..39) — Data Buffer Channel Number {n}
0xC07C AD_DIO_Ingress_BCN_Table_1_Row_10_Register — (1 of 3, stride 256)
  [8n-314:8n-320] dbcn{n} (n=40..43) — Data Buffer Channel Number {n}
0xC080 AD_DIO_Ingress_BCN_Table_1_Row_11_Register — (1 of 3, stride 256)
  [8n-346:8n-352] dbcn{n} (n=44..47) — Data Buffer Channel Number {n}
0xC084 AD_DIO_Ingress_BCN_Table_1_Row_12_Register — (1 of 3, stride 256)
  [8n-378:8n-384] dbcn{n} (n=48..51) — Data Buffer Channel Number {n}
0xC088 AD_DIO_Ingress_BCN_Table_1_Row_13_Register — (1 of 3, stride 256)
  [8n-410:8n-416] dbcn{n} (n=52..55) — Data Buffer Channel Number {n}
0xC08C AD_DIO_Ingress_BCN_Table_1_Row_14_Register — (1 of 3, stride 256)
  [8n-442:8n-448] dbcn{n} (n=56..59) — Data Buffer Channel Number {n}
0xC090 AD_DIO_Ingress_BCN_Table_1_Row_15_Register — (1 of 3, stride 256)
  [8n-474:8n-480] dbcn{n} (n=60..63) — Data Buffer Channel Number {n}
0xC300 AD_DIO_Egress_Table_Select_Register — (1 of 3, stride 256)
  fields as AD_DIO_Ingress_Table_Select_Register
0xC304 AD_DIO_Egress_Table_Loop_Configuration_Register — (1 of 3, stride 256)
  fields as AD_DIO_Ingress_Table_Loop_Configuration
0xC308 AD_DIO_Egress_DMA_Configuration_Register_0 — (1 of 3, stride 256)
  [28:16] dma_num_blks — Set the number of data blocks to transfer before wrapping back to dma_base_addr.
  [8] dma_ch_en — Enable channel DMA.
  [4] rsa_en — Configure channel DMA for RSA data format
  [1:0] dma_brst_ln — Sets the maximum DMA burst length.
0xC30C AD_DIO_Egress_DMA_Configuration_Register_1 — (1 of 3, stride 256)
  fields as AD_DIO_Ingress_DMA_Configuration_Register_1
0xC310 AD_DIO_Egress_DMA_Configuration_Register_2 — (1 of 3, stride 256)
  fields as AD_DIO_Ingress_DMA_Configuration_Register_2
0xC314 AD_DIO_Egress_BCN_Table_0_Row_0_Register — (1 of 3, stride 256)
  [8n+6:8n] dbcn{n} (n=0..3) — Data Buffer Channel Number {n}
0xC318 AD_DIO_Egress_BCN_Table_0_Row_1_Register — (1 of 3, stride 256)
  [8n-26:8n-32] dbcn{n} (n=4..7) — Data Buffer Channel Number {n}
0xC31C AD_DIO_Egress_BCN_Table_0_Row_2_Register — (1 of 3, stride 256)
  [8n-58:8n-64] dbcn{n} (n=8..11) — Data Buffer Channel Number {n}
0xC320 AD_DIO_Egress_BCN_Table_0_Row_3_Register — (1 of 3, stride 256)
  [8n-90:8n-96] dbcn{n} (n=12..15) — Data Buffer Channel Number {n}
0xC324 AD_DIO_Egress_BCN_Table_0_Row_4_Register — (1 of 3, stride 256)
  [8n-122:8n-128] dbcn{n} (n=16..19) — Data Buffer Channel Number {n}
0xC328 AD_DIO_Egress_BCN_Table_0_Row_5_Register — (1 of 3, stride 256)
  [8n-154:8n-160] dbcn{n} (n=20..23) — Data Buffer Channel Number {n}
0xC32C AD_DIO_Egress_BCN_Table_0_Row_6_Register — (1 of 3, stride 256)
  [8n-186:8n-192] dbcn{n} (n=24..27) — Data Buffer Channel Number {n}
0xC330 AD_DIO_Egress_BCN_Table_0_Row_7_Register — (1 of 3, stride 256)
  [8n-218:8n-224] dbcn{n} (n=28..31) — Data Buffer Channel Number {n}
0xC334 AD_DIO_Egress_BCN_Table_0_Row_8_Register — (1 of 3, stride 256)
  [8n-250:8n-256] dbcn{n} (n=32..35) — Data Buffer Channel Number {n}
0xC338 AD_DIO_Egress_BCN_Table_0_Row_9_Register — (1 of 3, stride 256)
  [8n-282:8n-288] dbcn{n} (n=36..39) — Data Buffer Channel Number {n}
0xC33C AD_DIO_Egress_BCN_Table_0_Row_10_Register — (1 of 3, stride 256)
  [8n-314:8n-320] dbcn{n} (n=40..43) — Data Buffer Channel Number {n}
0xC340 AD_DIO_Egress_BCN_Table_0_Row_11_Register — (1 of 3, stride 256)
  [8n-346:8n-352] dbcn{n} (n=44..47) — Data Buffer Channel Number {n}
0xC344 AD_DIO_Egress_BCN_Table_0_Row_12_Register — (1 of 3, stride 256)
  [8n-378:8n-384] dbcn{n} (n=48..51) — Data Buffer Channel Number {n}
0xC348 AD_DIO_Egress_BCN_Table_0_Row_13_Register — (1 of 3, stride 256)
  [8n-410:8n-416] dbcn{n} (n=52..55) — Data Buffer Channel Number {n}
0xC34C AD_DIO_Egress_BCN_Table_0_Row_14_Register — (1 of 3, stride 256)
  [8n-442:8n-448] dbcn{n} (n=56..59) — Data Buffer Channel Number {n}
0xC350 AD_DIO_Egress_BCN_Table_0_Row_15_Register — (1 of 3, stride 256)
  [8n-474:8n-480] dbcn{n} (n=60..63) — Data Buffer Channel Number {n}
0xC354 AD_DIO_Egress_BCN_Table_1_Row_0_Register — (1 of 3, stride 256)
  [8n+6:8n] dbcn{n} (n=0..3) — Data Buffer Channel Number {n}
0xC358 AD_DIO_Egress_BCN_Table_1_Row_1_Register — (1 of 3, stride 256)
  [8n-26:8n-32] dbcn{n} (n=4..7) — Data Buffer Channel Number {n}
0xC35C AD_DIO_Egress_BCN_Table_1_Row_2_Register — (1 of 3, stride 256)
  [8n-58:8n-64] dbcn{n} (n=8..11) — Data Buffer Channel Number {n}
0xC360 AD_DIO_Egress_BCN_Table_1_Row_3_Register — (1 of 3, stride 256)
  [8n-90:8n-96] dbcn{n} (n=12..15) — Data Buffer Channel Number {n}
0xC364 AD_DIO_Egress_BCN_Table_1_Row_4_Register — (1 of 3, stride 256)
  [8n-122:8n-128] dbcn{n} (n=16..19) — Data Buffer Channel Number {n}
0xC368 AD_DIO_Egress_BCN_Table_1_Row_5_Register — (1 of 3, stride 256)
  [8n-154:8n-160] dbcn{n} (n=20..23) — Data Buffer Channel Number {n}
0xC36C AD_DIO_Egress_BCN_Table_1_Row_6_Register — (1 of 3, stride 256)
  [8n-186:8n-192] dbcn{n} (n=24..27) — Data Buffer Channel Number {n}
0xC370 AD_DIO_Egress_BCN_Table_1_Row_7_Register — (1 of 3, stride 256)
  [8n-218:8n-224] dbcn{n} (n=28..31) — Data Buffer Channel Number {n}
0xC374 AD_DIO_Egress_BCN_Table_1_Row_8_Register — (1 of 3, stride 256)
  [8n-250:8n-256] dbcn{n} (n=32..35) — Data Buffer Channel Number {n}
0xC378 AD_DIO_Egress_BCN_Table_1_Row_9_Register — (1 of 3, stride 256)
  [8n-282:8n-288] dbcn{n} (n=36..39) — Data Buffer Channel Number {n}
0xC37C AD_DIO_Egress_BCN_Table_1_Row_10_Register — (1 of 3, stride 256)
  [8n-314:8n-320] dbcn{n} (n=40..43) — Data Buffer Channel Number {n}
0xC380 AD_DIO_Egress_BCN_Table_1_Row_11_Register — (1 of 3, stride 256)
  [8n-346:8n-352] dbcn{n} (n=44..47) — Data Buffer Channel Number {n}
0xC384 AD_DIO_Egress_BCN_Table_1_Row_12_Register — (1 of 3, stride 256)
  [8n-378:8n-384] dbcn{n} (n=48..51) — Data Buffer Channel Number {n}
0xC388 AD_DIO_Egress_BCN_Table_1_Row_13_Register — (1 of 3, stride 256)
  [8n-410:8n-416] dbcn{n} (n=52..55) — Data Buffer Channel Number {n}
0xC38C AD_DIO_Egress_BCN_Table_1_Row_14_Register — (1 of 3, stride 256)
  [8n-442:8n-448] dbcn{n} (n=56..59) — Data Buffer Channel Number {n}
0xC390 AD_DIO_Egress_BCN_Table_1_Row_15_Register — (1 of 3, stride 256)
  [8n-474:8n-480] dbcn{n} (n=60..63) — Data Buffer Channel Number {n}
0xC600 AD_DIO_Data_Trace_DMA_Configuration_Register_0
  [1] dt_dma_fm_ch_en — Enable data trace framing dtaa channel DMA.
  [0] dt_dma_rd_ch_en — Enable data trace receive data channel DMA.
0xC604 AD_DIO_Data_Trace_DMA_Configuration_Register_1
  [27:0] dt_dma_rd_base_addr — Sets the destination VBUS base address (upper 28 bits of 32 bit data bus) for data trace receive data.
0xC608 AD_DIO_Data_Trace_DMA_Configuration_Register_2
  [27:0] dt_dma_fm_base_addr — Sets the destination VBUS base address (upper 28 bits of 32 bit data bus) for data trace framing data.
0xC60C AD_DIO_Data_Trace_DMA_Configuration_Register_3
  [17:0] dt_dma_wrap — Sets the number of burst transfers before the destination address wraps back to the base address.
0xC610 AD_DIO_Ingress_Global_Enable_Set_Register wo — Set Global Enable for AD Ingress DIO
  [31:0] DONT_CARE — A write of any value to this register sets the global enable for the AD Ingress DIO
0xC614 AD_DIO_Ingress_Global_Enable_Clear_Register wo — Clear Global Enable for AD Ingress DIO
  [31:0] DONT_CARE — A write of any value to this register clears the global enable for the AD Ingress DIO
0xC618 AD_DIO_Ingress_Global_Enable_Status_Register ro — Read Only status of AD Ingress DIO global enable state.
  [0] ENABLE — 0x1: AD Ingress DIO_ON 0x0:AD Ingress DIO OFF
0xC61C AD_DIO_Egress_Global_Enable_Set_Register wo — Set Global Enable for AD Egress DIO
  [31:0] DONT_CARE — A write of any value to this register sets the global enable for the AD Egress DIO
0xC620 AD_DIO_Egress_Global_Enable_Clear_Register wo — Clear Global Enable for AD Egress DIO
  [31:0] DONT_CARE — A write of any value to this register clears the global enable for the AD Egress DIO
0xC624 AD_DIO_Egress_Global_Enable_Status_Register ro — Read Only status of AD Egress DIO global enable state.
  [0] ENABLE — 0x1: AD Egress DIO_ON 0x0:AD Egress DIO OFF
0xE000 AD_Scheduler_Ingress_Configuration_Register
  [16] pri — This field controls the Ingress Scheduler aribitration priority
  [0] fail_mode — This field controls how the Ingress Scheduler handles packets marked as failed by the PD.
0xE004 AD_Scheduler_Ingress_Global_Enable_Set_Register wo — Set Global Enable for AD Ingress Scheduler
  [31:0] DONT_CARE — A write of any value to this register sets the global enable for the AD Ingress Scheduler
0xE008 AD_Scheduler_Ingress_Global_Enable_Clear wo — Clear Global Enable for AD Ingress Scheduler
  [31:0] DONT_CARE — A write of any value to this register clears the global enable for the AD Ingress Scheduler
0xE00C AD_Scheduler_Ingress_Global_Enable_Status ro — Read Only status of AD Ingress Scheduler global enable state.
  [0] ENABLE — 0x1: AD Ingress Scheduler_ON 0x0:AD Ingress Scheduler OFF
